# SAM9X75D5MN0 device description
Architecture: ARM926EJ-S; Family: SAM9; Series: SAM9X7
Registers are 32-bit, read-write, reset 0x0 unless marked. A register's access mark holds for its fields unless they carry their own. Offsets are from the block's base; [hi:lo] are bit positions; {n}, {i} and the like mark numbered series.

## TDES — Triple Data Encryption Standard
Instances: TDES 0xF0038000
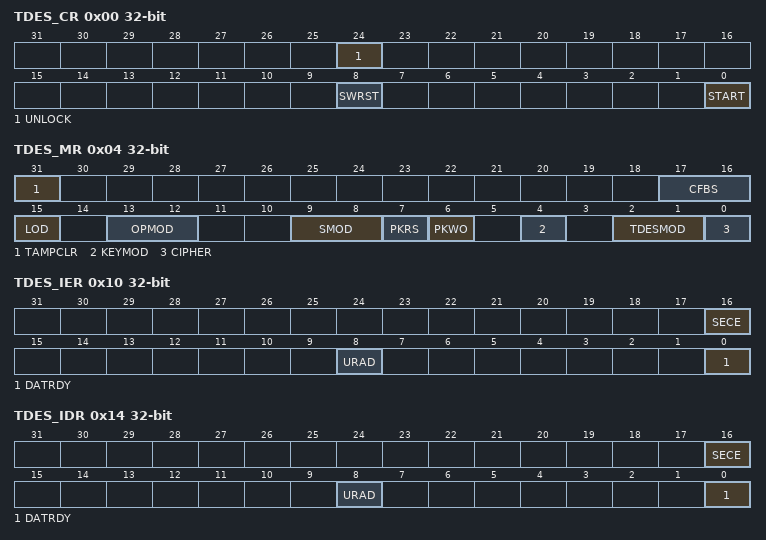
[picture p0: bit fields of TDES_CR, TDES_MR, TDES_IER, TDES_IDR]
0x00 TDES_CR wo reset not defined — Control Register
  [24] UNLOCK — Unlock Processing
    0=No effect; 1=Unlocks the processing in case of abnormal event detection if TDES_WPMR.ACTION > 0
  [8] SWRST — Software Reset
    0=No effect; 1=Resets the TDES. A software-triggered reset of the TDES interface is performed.
  [0] START — Start Processing
    0=No effect; 1=Starts Manual encryption/decryption process
0x04 TDES_MR — Mode Register
  [31] TAMPCLR — Tamper Pin Clear Key Enable
    0=A tamper detection event has no effect on TDES_KEYxWRy; 1=A tamper detection event immediately clears TDES_KEYxWRy
  [17:16] CFBS — Cipher Feedback Data Size
    0=SIZE_64BIT (64-bit); 1=SIZE_32BIT (32-bit); 2=SIZE_16BIT (16-bit); 3=SIZE_8BIT (8-bit)
  [15] LOD — Last Output Data Mode
    0=No effect; 1=The DATRDY flag is cleared when at least one of the TDES_IDATARx is written
  [13:12] OPMOD — Operating Mode
    0=ECB (Electronic Code Book mode); 1=CBC (Cipher Block Chaining mode); 2=OFB (Output Feedback mode); 3=CFB (Cipher Feedback mode)
  [9:8] SMOD — Start Mode
    0=MANUAL_START (Manual Mode); 1=AUTO_START (Auto Mode); 2=IDATAR0_START (TDES_IDATAR0 accesses only Auto mode)
  [7] PKRS — Private Key Internal Register Select
    0=The keys used by the TDES are in the TDES_KEY1WRy, TDES_KEY2WRy and TDES_KEY3WRy registers; 1=The keys used by the TDES are the in the Private Key internal registers written through the Private Key bus
  [6] PKWO — Private Key Write Once
    0=The Private Key internal registers can be written multiple times through the Private Key bus; 1=The Private Key internal registers can be written only once through the Private Key bus until hardware reset
  [4] KEYMOD — Key Mode
    0=Three-key algorithm is selected; 1=Two-key algorithm is selected. There is no need to write TDES_KEY3WRy (or Private Key internal registers with more than 128 bits).
  [2:1] TDESMOD — ALGORITHM Mode
    0=SINGLE_DES (Single DES processing using TDES_KEY1WRy.); 1=TRIPLE_DES (Triple DES processing using TDES_KEY1WRy, TDES_KEY2WRy and TDES_KEY3WRy.); 2=XTEA (XTEA processing using TDES_KEY1WRy and TDES_KEY2WRy.)
  [0] CIPHER — Processing Mode
    0=DECRYPT (Decrypts data.); 1=ENCRYPT (Encrypts data.)
0x10 TDES_IER wo reset not defined (atomic set of TDES_IMR) — Interrupt Enable Register
  [16] SECE — Security and/or Safety Event Interrupt Enable
  [8] URAD — Unspecified Register Access Detection Interrupt Enable
  [0] DATRDY — Data Ready Interrupt Enable
0x14 TDES_IDR wo reset not defined (atomic clear of TDES_IMR) — Interrupt Disable Register
  [16] SECE — Security and/or Safety Event Interrupt Disable
  [8] URAD — Unspecified Register Access Detection Interrupt Disable
  [0] DATRDY — Data Ready Interrupt Disable
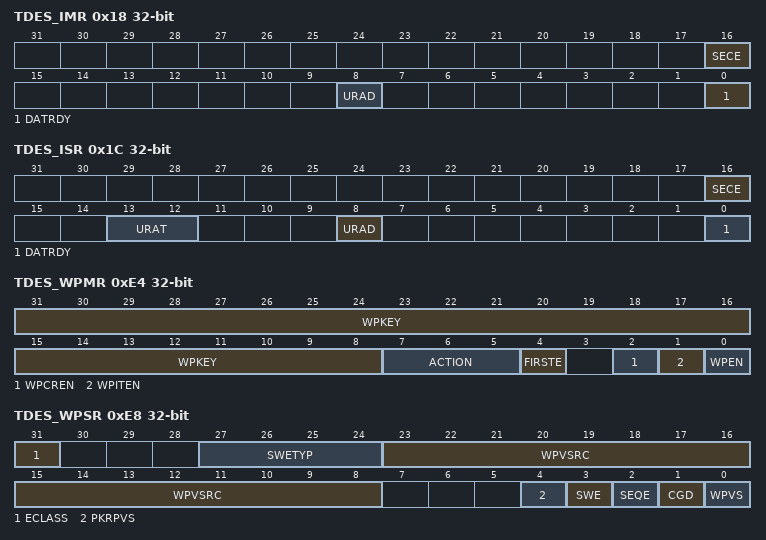
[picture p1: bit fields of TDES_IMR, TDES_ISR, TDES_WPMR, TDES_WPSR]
0x18 TDES_IMR ro — Interrupt Mask Register
  [16] SECE — Security and/or Safety Event Interrupt Mask
  [8] URAD — Unspecified Register Access Detection Interrupt Mask
  [0] DATRDY — Data Ready Interrupt Mask
0x1C TDES_ISR ro — Interrupt Status Register
  [16] SECE — Security and/or Safety Event Interrupt Mask
    0=There is no security report in TDES_WPSR; 1=One security flag is set in TDES_WPSR
  [13:12] URAT — Unspecified Register Access (cleared by setting TDES_CR.SWRST)
    0=IDR_WR_PROCESSING (TDES_IDATAR written during data processing when SMOD = 0x2 mode.); 1=ODR_RD_PROCESSING (TDES_ODATAR read during data processing.); 2=MR_WR_PROCESSING (TDES_MR written during data processing.); 3=WOR_RD_ACCESS (Write-only register read access.)
  [8] URAD — Unspecified Register Access Detection Status (cleared by setting TDES_CR.SWRST)
    0=No unspecified register access has been detected since the last write of TDES_CR.SWRST; 1=At least one unspecified register access has been detected since the last write of TDES_CR.SWRST
  [0] DATRDY — Data Ready (cleared by setting TDES_CR.START or TDES_CR.SWRST, or by reading TDES_ODATARx)
    0=Output data is not valid; 1=Encryption or decryption process is completed
{0x20+4i} TDES_KEY1WR[{i}] (i=0..1) wo reset not defined — Key 1 Word Register x
  [31:0] KEY1W — Key 1 Word
{0x28+4i} TDES_KEY2WR[{i}] (i=0..1) wo reset not defined — Key 2 Word Register x
  [31:0] KEY2W — Key 2 Word
{0x30+4i} TDES_KEY3WR[{i}] (i=0..1) wo reset not defined — Key 3 Word Register x
  [31:0] KEY3W — Key 3 Word
{0x40+4i} TDES_IDATAR[{i}] (i=0..1) wo reset not defined — Input Data Register x
  [31:0] IDATA — Input Data
{0x50+4i} TDES_ODATAR[{i}] (i=0..1) ro — Output Data Register x
  [31:0] ODATA — Output Data
{0x60+4i} TDES_IVR[{i}] (i=0..1) wo reset not defined — Initialization Vector Register x
  [31:0] IV — Initialization Vector
0x70 TDES_XTEA_RNDR — XTEA Rounds Register
  [5:0] XTEA_RNDS — Number of Rounds
0xE4 TDES_WPMR — Write Protection Mode Register
  [31:8] WPKEY — Write Protection Key
    0x444553=PASSWD (Writing any other value in this field aborts the write operation of bits WPEN, WPITEN and WPCREN. Always reads as 0.)
  [7:5] ACTION — Action on Abnormal Event Detection
    0=REPORT_ONLY (No action (stop or clear key) is performed when one of PKRPVS, WPVS, CGD, SEQE, or SWE flags are set.); 1=LOCK_PKRPVS_WPVS_SWE (If a processing is in progress when the TDES_WPSR.PKRPVS/WPVS/SWE event detection occurs, the current processing is ended normally but no other processing is started while a TDES_CR.UNLOCK command is issued.); 2=LOCK_CGD_SEQE (If a processing is in progress when the TDES_WPSR.CGD/SEQE event detection occurs, the current processing is ended normally but no other processing is started while a TDES_CR.UNLOCK command is issued.); 3=LOCK_ANY_EV (If a processing is in progress when the TDES_WPSR.PKRPVS/WPVS/CGD/SEQE/SWE events detection occurs, the current processing is ended normally but no other processing is started while a TDES_CR.UNLOCK command is issued.); 4=CLEAR_PKRPVS_WPVS_SWE (If a processing is in progress when the TDES_WPSR.PKRPVS/WPVS/SWE events detection occurs, the current processing is ended normally but no other processing is started while a TDES_CR.UNLOCK command is issued. Moreover, TDES_KEYxWRy are immediately cleared.); 5=CLEAR_CGD_SEQE (If a processing is in progress when the TDES_WPSR.CGD/SEQE events detection occurs, the current processing is ended normally but no other processing is started while a TDES_CR.UNLOCK command is issued. Moreover, TDES_KEYxWRy are immediately cleared.); 6=CLEAR_ANY_EV (If a processing is in progress when the TDES_WPSR.PKRPVS/WPVS/CGD/SEQE/SWE events detection occurs, the current processing is ended normally but no other processing is started while a TDES_CR.UNLOCK command is issued. Moreover, TDES_KEYxWRy are immediately cleared.)
  [4] FIRSTE — First Error Report Enable
    0=The last write protection violation source is reported in TDES_WPSR.WPVSRC and the last software control error type is reported in TDES_WPSR.SWETYP. The TDES_ISR.SECE flag is set at the first error occurrence within a series.; 1=Only the first write protection violation source is reported in TDES_WPSR.WPVSRC and only the first software control error type is reported in TDES_WPSR.SWETYP. The TDES_ISR.SECE flag is set at the first error occurrence within a series.
  [2] WPCREN — Write Protection Control Enable
    0=Disables the write protection on control register if WPKEY corresponds to0x444553 ("DES" in ASCII); 1=Enables the write protection on control register if WPKEY corresponds to 0x444553 ("DES" in ASCII)
  [1] WPITEN — Write Protection Interrupt Enable
    0=Disables the write protection on interrupt registers if WPKEY corresponds to 0x444553 ("DES" in ASCII); 1=Enables the write protection on interrupt registers if WPKEY corresponds to 0x444553 ("DES" in ASCII)
  [0] WPEN — Write Protection Enable
    0=Disables the write protection if WPKEY corresponds to 0x444553 ("DES" in ASCII); 1=Enables the write protection if WPKEY corresponds to 0x444553 ("DES" in ASCII)
0xE8 TDES_WPSR ro — Write Protection Status Register
  [31] ECLASS — Software Error Class (cleared on read)
    0=WARNING (An abnormal access that does not affect system functionality.); 1=ERROR (An access is performed into key, input data, control registers while the TDES is performing an encryption/decryption or a start is request by software or DMA while the key is not fully configured.)
  [27:24] SWETYP — Software Error Type (cleared on read)
    0=READ_WO (A write-only register has been read (Warning).); 1=WRITE_RO (TDES is enabled and a write access has been performed on a read-only register (Warning).); 2=UNDEF_RW (Access to an undefined address (Warning).); 3=CTRL_START (Abnormal use of TDES_CR.START command when DMA access is configured.); 4=WEIRD_ACTION (A key write, init value write, output data read, Mode register write, Private Key bus access or XTEA round register has been performed while a current processing is in progress (abnormal).); 5=INCOMPLETE_KEY (A tentative of start is required while the keys are not fully loaded into TDES_KEYxWRy.)
  [23:8] WPVSRC — Write Protection Violation Source (cleared on read)
  [4] PKRPVS — Private Key Register Protection Violation Status (cleared on read)
    0=No Private Key internal register access violation has occurred since the last read of TDES_WPSR; 1=A Private Key internal register access violation has occurred since the last read of TDES_WPSR
  [3] SWE — Software Control Error (cleared on read)
    0=No software error has occurred since the last read of TDES_WPSR; 1=A software error has occurred since the last read of TDES_WPSR. The field SWETYP details the type of software error; the associated incorrect software access is reported in the field WPVSRC (if WPVS=0).
  [2] SEQE — Internal Sequencer Error (cleared on read)
    0=No peripheral internal sequencer error has occurred since the last read of TDES_WPSR; 1=A peripheral internal sequencer error has occurred since the last read of TDES_WPSR. This flag is set under abnormal operating conditions.
  [1] CGD — Clock Glitch Detected (cleared on read)
    0=The clock monitoring circuitry has not been corrupted since the last read of TDES_WPSR. Under normal operating conditions, this bit is always cleared.; 1=The clock monitoring circuitry has been corrupted since the last read of TDES_WPSR. This flag is set in case of abnormal clock signal waveform (glitch).
  [0] WPVS — Write Protection Violation Status (cleared on read)
    0=No write protection violation has occurred since the last read of TDES_WPSR; 1=A write protection violation has occurred since the last read of TDES_WPSR. If this violation is an unauthorized attempt to write a protected register, the associated violation is reported into field WPVSRC.
